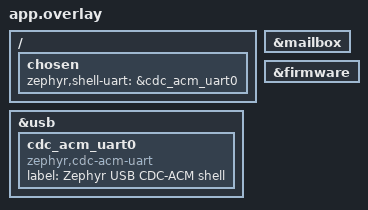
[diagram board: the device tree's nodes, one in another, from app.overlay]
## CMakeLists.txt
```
# SPDX-License-Identifier: Apache-2.0

cmake_minimum_required(VERSION 3.20.0)

find_package(Zephyr REQUIRED HINTS $ENV{ZEPHYR_BASE})
project(rpi_zero_2w_usb_cdc_shell)

target_sources(app PRIVATE src/main.c)
```

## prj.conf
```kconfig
# USB device stack (new / device_next)
CONFIG_USB_DEVICE_STACK_NEXT=y
CONFIG_UDC_DWC2=y
CONFIG_UDC_DWC2_DMA=n

# CDC ACM class -- turnkey init at SYS_INIT.
CONFIG_SERIAL=y
CONFIG_USBD_CDC_ACM_CLASS=y
CONFIG_CDC_ACM_SERIAL_INITIALIZE_AT_BOOT=y

# VC mailbox + firmware (USB PHY power-on via SET_POWER_STATE +
# board serial via GET_BOARD_SERIAL for iSerialNumber).
CONFIG_BCM2835_MBOX=y
CONFIG_BCM2835_FIRMWARE=y
CONFIG_HWINFO=y

# AArch64 USBD/UDC stack bumps -- defaults overflow on the
# usbd_thread call chain through CDC ACM + shell. Stack sentinel
# is a future-tripwire (memory:
# feedback_zephyr_stack_sentinel_for_corruption_hunts).
CONFIG_USBD_THREAD_STACK_SIZE=4096
CONFIG_UDC_DWC2_STACK_SIZE=4096
CONFIG_STACK_SENTINEL=y
CONFIG_ASSERT=y

# Shell subsystem on the CDC ACM UART (selected via chosen
# `zephyr,shell-uart` in the app overlay). The shell starts its
# own thread; main() just goes idle. Routing logs through the
# shell backend keeps the prompt readable even when LOG_INF fires
# mid-line.
CONFIG_SHELL=y
CONFIG_SHELL_BACKEND_SERIAL=y
CONFIG_SHELL_LOG_BACKEND=y

# Useful shell commands for poking at the device:
#   `device list`        - all bound devices incl. DWC2 controller
#   `kernel threads`     - see usbd / udc / shell stack usage
#   `hwinfo devid`       - prints the 64-bit Pi OTP serial
CONFIG_DEVICE_SHELL=y
CONFIG_KERNEL_SHELL=y
CONFIG_HWINFO_SHELL=y

# PL011 console + LOG. Boot logs still go to PL011 (the chosen
# zephyr,console); shell I/O is on USB CDC ACM. Quiet defaults
# elsewhere -- enable DBG locally if regressing the bring-up flow.
CONFIG_PRINTK=y
CONFIG_LOG=y
CONFIG_LOG_BUFFER_SIZE=8192
CONFIG_USBD_CDC_ACM_LOG_LEVEL_INF=y
CONFIG_BCM2835_FIRMWARE_LOG_LEVEL_INF=y
CONFIG_UDC_DRIVER_LOG_LEVEL_WRN=y
```

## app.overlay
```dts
/*
 * Zephyr shell over USB CDC ACM on rpi_zero_2w.
 *
 * Enables &usb / &mailbox / &firmware (same set as the parallel
 * usb_cdc_min sample) and declares a single CDC ACM UART child
 * on the USB controller. The `chosen` block points the shell
 * subsystem at that UART, so `CONFIG_SHELL=y` plus
 * `CONFIG_SHELL_BACKEND_SERIAL=y` automatically attaches a shell
 * prompt to /dev/cu.usbmodem* on the host.
 *
 * The PL011 console (zephyr,console / zephyr,uart-mcumgr defaults
 * from the board) keeps its boot-log duty -- chosen is the only
 * difference here, only re-routing the shell.
 */

&mailbox {
	status = "okay";
};

&firmware {
	status = "okay";
};

&usb {
	status = "okay";

	cdc_acm_uart0: cdc_acm_uart0 {
		compatible = "zephyr,cdc-acm-uart";
		label = "Zephyr USB CDC-ACM shell";
	};
};

/ {
	chosen {
		zephyr,shell-uart = &cdc_acm_uart0;
	};
};
```

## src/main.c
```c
/*
 * Copyright (c) 2026 jetpax
 *
 * SPDX-License-Identifier: Apache-2.0
 *
 * Zephyr shell over USB CDC ACM on rpi_zero_2w.
 *
 * Nothing for main() to do -- the shell subsystem starts its own
 * thread at SYS_INIT and binds to the UART named in the DT chosen
 * `zephyr,shell-uart` (set to the CDC ACM instance in app.overlay).
 * Host opens /dev/cu.usbmodem* and gets a `uart:~$ ` prompt.
 *
 * Try:
 *   uart:~$ help
 *   uart:~$ kernel threads
 *   uart:~$ device list
 *   uart:~$ hwinfo devid       # the 64-bit Pi OTP serial
 *   uart:~$ log enable inf udc_dwc2  # live-flip log levels
 */

int main(void)
{
	return 0;
}
```
